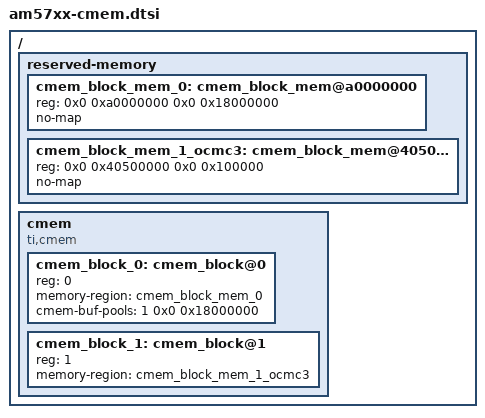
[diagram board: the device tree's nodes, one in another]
/* https://git.yoctoproject.org/cgit/cgit.cgi/meta-ti/tree/recipes-kernel/linux/files/dra7xx/cmem.dtsi?h=thud */
/* 0x0c000000 -> 0x18000000 for tild */

/ {
        reserved-memory {
                #address-cells = <2>;
                #size-cells = <2>;
                ranges;

                cmem_block_mem_0: cmem_block_mem@a0000000 {
                        reg = <0x0 0xa0000000 0x0 0x18000000>;
                        no-map;
                        status = "okay";
                };

		cmem_block_mem_1_ocmc3: cmem_block_mem@40500000 {
			reg = <0x0 0x40500000 0x0 0x100000>;
			no-map;
			status = "okay";
		};
        };

        cmem {
                compatible = "ti,cmem";
                #address-cells = <1>;
                #size-cells = <0>;

		#pool-size-cells = <2>;

                status = "okay";

                cmem_block_0: cmem_block@0 {
                        reg = <0>;
                        memory-region = <&cmem_block_mem_0>;
                        cmem-buf-pools = <1 0x0 0x18000000>;
                };

		cmem_block_1: cmem_block@1 {
			reg = <1>;
			memory-region = <&cmem_block_mem_1_ocmc3>;
		};
        };
};
